# STM32H7R register map
File version: 1.3
CPU: CM7 r0p1, little endian, MPU, FPU, 4 interrupt priority bits
Registers are 32-bit, read-write, reset 0x0 unless marked. A register's access mark holds for its fields unless they carry their own. Offsets are from the block's base; [hi:lo] are bit positions; lines under a group give offsets from that group; {n}, {i} and the like mark numbered series.

## CRC — Cyclic redundancy check calculation unit
Base 0x58024C00
0x00 DR reset 0xFFFFFFFF — CRC data register
  [31:0] DR — Data register bits This register is used to write new data to the CRC calculator. It holds the previous CRC calculation result when it is read. If the data size is less than 32 bits, the least significant bits are used to write/read the correct value.
0x00 DR8 8-bit reset 0xFF (alternate view of DR) — Data register - byte sized
  [7:0] DR8 — Data register bits
0x00 DR16 16-bit reset 0xFFFF (alternate view of DR) — Data register - half-word sized
  [15:0] DR16 — Data register bits
0x04 IDR — CRC independent data register
  [31:0] IDR — General-purpose 32-bit data register bits These bits can be used as a temporary storage location for four bytes. This register is not affected by CRC resets generated by the RESET bit in the CRC_CR register
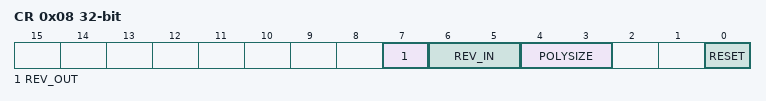
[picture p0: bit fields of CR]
0x08 CR — CRC control register
  [7] REV_OUT — Reverse output data This bit controls the reversal of the bit order of the output data.
    0=Normal (Bit order not affected); 1=Reversed (Bit reversed output)
  [6:5] REV_IN — Reverse input data This bitfield controls the reversal of the bit order of the input data
    0=Normal (Bit order not affected); 1=Byte (Bit reversal done by byte); 2=HalfWord (Bit reversal done by half-word); 3=Word (Bit reversal done by word)
  [4:3] POLYSIZE — Polynomial size These bits control the size of the polynomial.
    0=32-bit polynomial; 1=16-bit polynomial; 2=8-bit polynomial; 3=7-bit polynomial
  [0] RESET — RESET bit This bit is set by software to reset the CRC calculation unit and set the data register to the value stored in the CRC_INIT register. This bit can only be set, it is automatically cleared by hardware
    on write: 1=Resets the CRC calculation unit and sets the data register to 0xFFFF FFFF
0x10 INIT reset 0xFFFFFFFF — CRC initial value
  [31:0] INIT — Programmable initial CRC value This register is used to write the CRC initial value.
0x14 POL reset 0x4C11DB7 — CRC polynomial
  [31:0] POL — Programmable polynomial This register is used to write the coefficients of the polynomial to be used for CRC calculation. If the polynomial size is less than 32 bits, the least significant bits have to be used to program the correct value.

## DLYB1 — DLYB register block
Base 0x52008000
Same registers: DLYB2 0x48002800
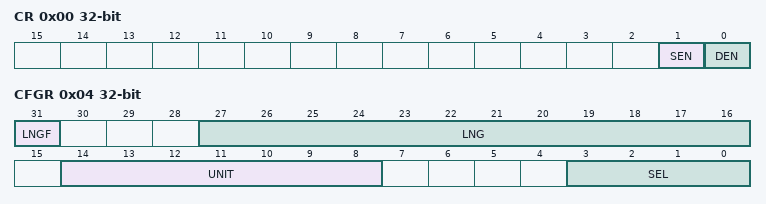
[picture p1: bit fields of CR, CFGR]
0x00 CR — DLYB control register
  [1] SEN — Sampler length enable bit
  [0] DEN — Delay block enable bit
0x04 CFGR access per field — DLYB configuration register
  [31] LNGF ro — Length valid flag This flag indicates when the delay line length value contained in LNG[11:0] is valid after UNIT[6:0] bits changed.
  [27:16] LNG ro — Delay line length value These bits reflect the 12 unit delay values sampled at the rising edge of the input clock. The value is only valid when LNGF = 1.
  [14:8] UNIT rw — Delay of a unit delay cell. These bits can only be written when SEN = 1. Unit delay = initial delay + UNIT[6:0] x delay step
  [3:0] SEL rw — Phase for the output clock. These bits can only be written when SEN = 1. Output clock phase = input clock + SEL[3:0] x unit delay

## GFXMMU — Chrom-GRC
Base 0x52010000
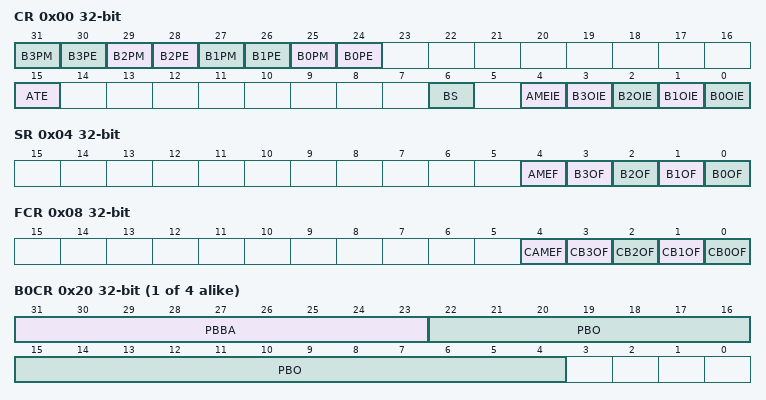
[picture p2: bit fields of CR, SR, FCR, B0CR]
0x00 CR — GFXMMU configuration register
  [2n+25] B{n}PM (n=0..3) — Buffer {n} packing mode This bit selects the byte to be removed during packing operations on buffer {n}
  [2n+24] B{n}PE (n=0..3) — Buffer {n} packing enable This bit enables the packing on buffer {n}. The packing is functional only if the block size is configured in 12-byte mode. In 16-byte mode, this bit is ignored.
  [15] ATE — Address translation enable This bit enables the address translation based on the values programmed in the LUT.
  [6] BS — Block size This bit defines the size of the blocks
  [4] AMEIE — AXI master error interrupt enable This bit enables the AXI master error interrupt.
  [n] B{n}OIE (n=0..3) — Buffer {n} overflow interrupt enable This bit enables the buffer {n} overflow interrupt.
0x04 SR ro — GFXMMU status register
  [4] AMEF — AXI master error flag This bit is set when an AXI error happens during a transaction. It is cleared by writing 1 to CAMEF.
  [n] B{n}OF (n=0..3) — Buffer {n} overflow flag This bit is set when an overflow occurs during the offset calculation of the buffer {n}. It is cleared by writing 1 to CB{n}OF.
0x08 FCR — GFXMMU flag clear register
  [4] CAMEF — Clear AXI master error flag Writing 1 clears the AXI master error flag in the GFXMMU_SR register.
  [n] CB{n}OF (n=0..3) — Clear buffer {n} overflow flag Writing 1 clears the buffer {n} overflow flag in the GFXMMU_SR register.
0x10 DVR — GFXMMU default value register
  [31:0] DV — Default value This field indicates the default 32-bit value which is returned when a master accesses a virtual memory location not physically mapped.
0x14 DAR — GFXMMU default alpha register
  [7:0] DA — Default alpha This field indicates the default 8-bit value which is merged with the 24-bit value when a master accesses a virtual memory location in packed mode.
{0x20+4i} B{i}CR (i=0..3) — GFXMMU buffer {i} configuration register
  [31:23] PBBA — Physical buffer base address Base address MSB of the physical buffer.
  [22:4] PBO — Physical buffer offset Offset of the physical buffer.
{0x1000+8i} LUT{i} (i=0..1023) group — Cluster LUT{i}, containing LUT*L, LUT*H
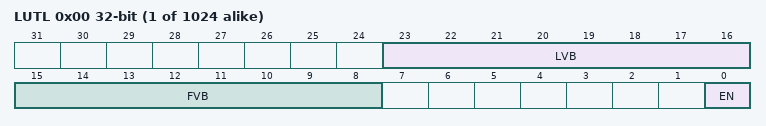
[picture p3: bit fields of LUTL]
  0x00 LUTL — Graphic MMU LUT entry x low
    [23:16] LVB — Last valid block Number of the last valid block of line number X.
    [15:8] FVB — First valid block Number of the first valid block of line number x.
    [0] EN — Enable Line enable.
  0x04 LUTH — Graphic MMU LUT entry x high
    [17:0] LO — Line offset Line offset of line number x expressed in number of blocks
